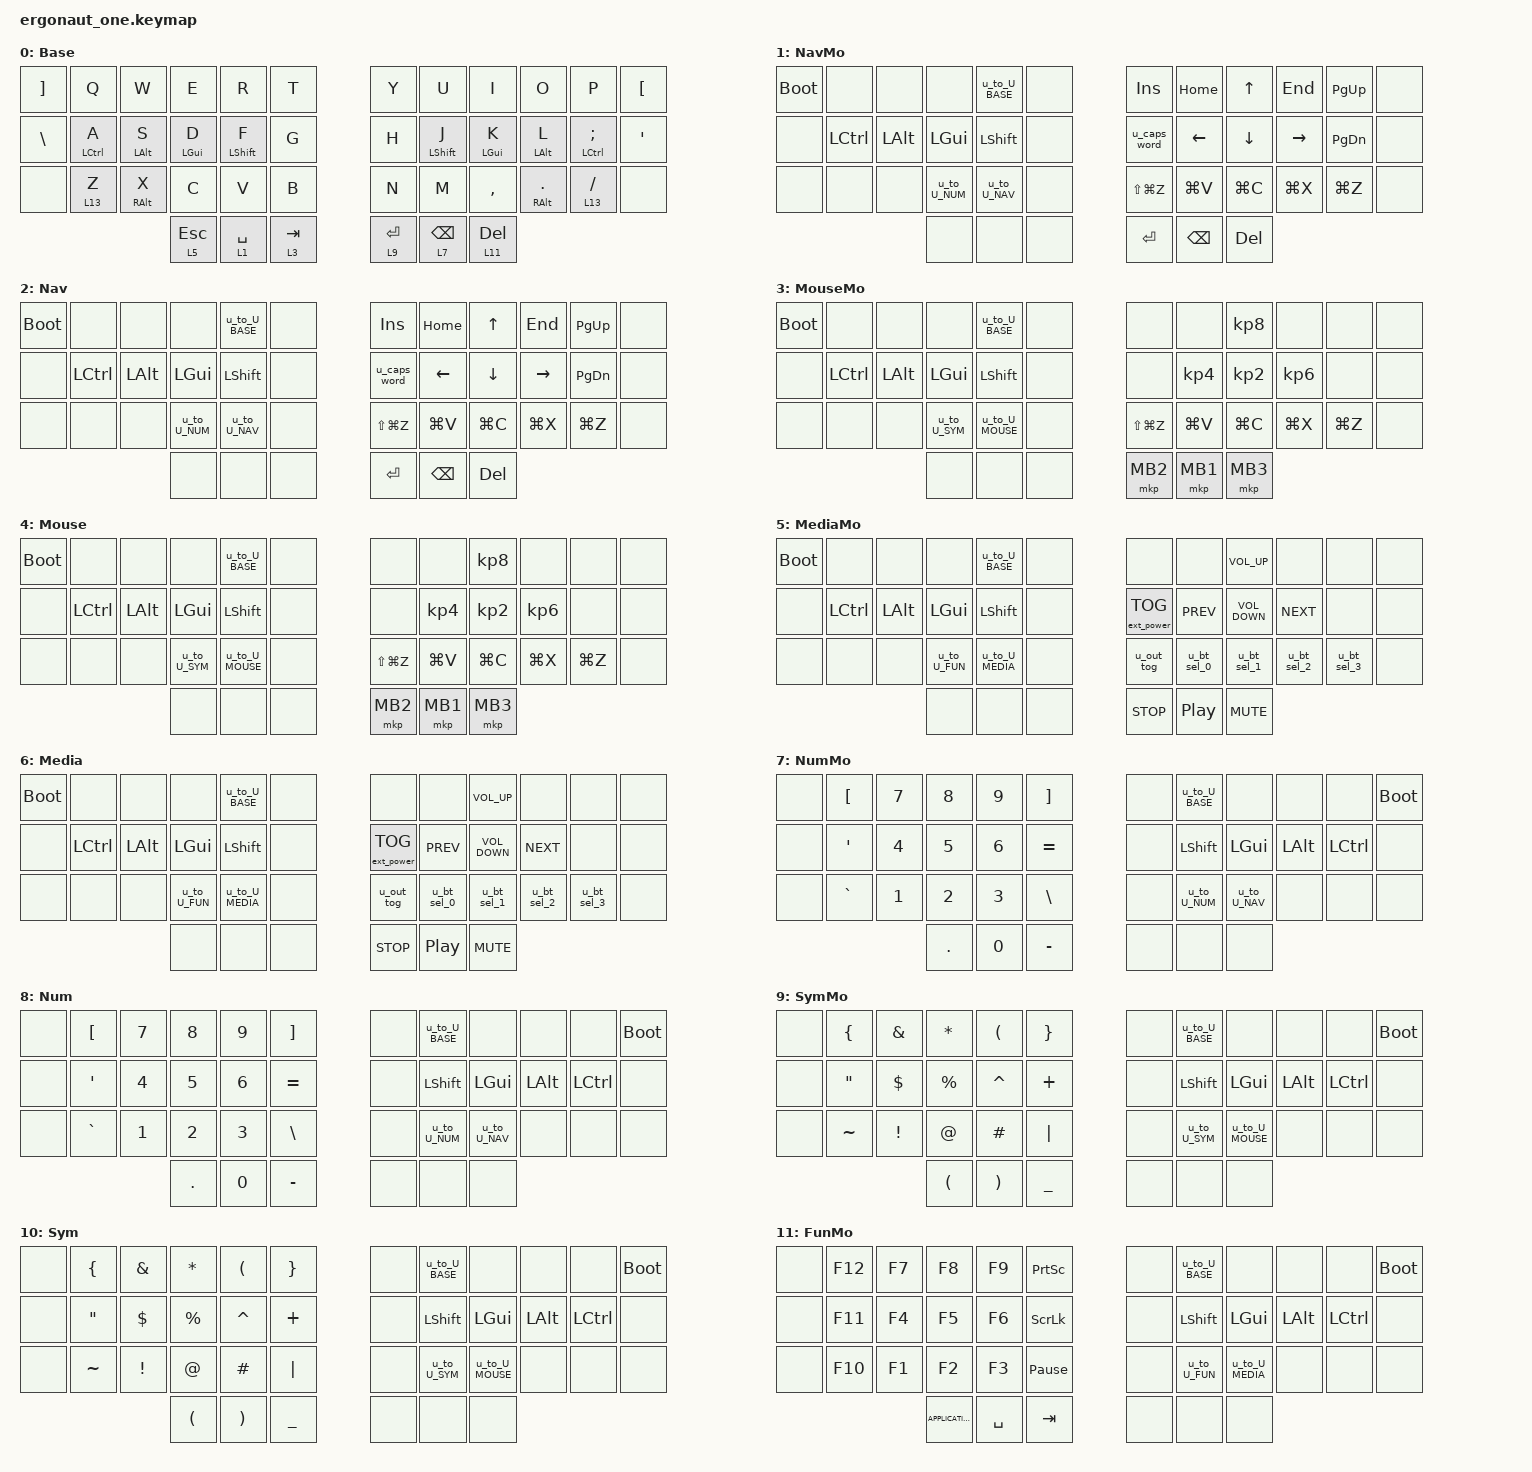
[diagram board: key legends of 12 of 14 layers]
#include <behaviors.dtsi>
#include <dt-bindings/zmk/bt.h>
#include <dt-bindings/zmk/ext_power.h>
#include <dt-bindings/zmk/keys.h>
#include <dt-bindings/zmk/mouse.h>
#include <dt-bindings/zmk/outputs.h>

#define DEF 0
#define LWR 1
#define RSE 2
#define ADJ 3

/ {
    conditional_layers { compatible = "zmk,conditional-layers"; };

    behaviors {
        hr: homerow_mods {
            compatible = "zmk,behavior-hold-tap";
            label = "HOMEROW_MODS";
            bindings = <&kp>, <&kp>;

            #binding-cells = <2>;
            tapping-term-ms = <200>;
            flavor = "tap-preferred";
        };

        u_caps_word: u_caps_word {
            compatible = "zmk,behavior-mod-morph";
            bindings = <&caps_word>, <&kp CAPSLOCK>;

            #binding-cells = <0>;
            mods = <(MOD_LSFT|MOD_RSFT)>;
        };

        u_lt: u_lt {
            compatible = "zmk,behavior-hold-tap";
            bindings = <&mo>, <&kp>;

            #binding-cells = <2>;
            tapping-term-ms = <200>;
            flavor = "tap-preferred";
        };

        u_to_U_BASE: u_to_U_BASE {
            compatible = "zmk,behavior-tap-dance";
            #binding-cells = <0>;
            tapping-term-ms = <200>;
            bindings = <&none>, <&to 0>;
        };

        u_to_U_FUN: u_to_U_FUN {
            compatible = "zmk,behavior-tap-dance";
            #binding-cells = <0>;
            tapping-term-ms = <200>;
            bindings = <&none>, <&to 12>;
        };

        u_to_U_SYM: u_to_U_SYM {
            compatible = "zmk,behavior-tap-dance";
            #binding-cells = <0>;
            bindings = <&none>, <&to 10>;

            tapping-term-ms = <200>;
        };

        u_to_U_NUM: u_to_U_NUM {
            compatible = "zmk,behavior-tap-dance";
            #binding-cells = <0>;
            tapping-term-ms = <200>;
            bindings = <&none>, <&to 8>;
        };

        u_to_U_MEDIA: u_to_U_MEDIA {
            compatible = "zmk,behavior-tap-dance";
            #binding-cells = <0>;
            tapping-term-ms = <200>;
            bindings = <&none>, <&to 6>;
        };

        u_to_U_MOUSE: u_to_U_MOUSE {
            compatible = "zmk,behavior-tap-dance";
            #binding-cells = <0>;
            tapping-term-ms = <200>;
            bindings = <&none>, <&to 4>;
        };

        u_to_U_NAV: u_to_U_NAV {
            compatible = "zmk,behavior-tap-dance";
            #binding-cells = <0>;
            tapping-term-ms = <200>;
            bindings = <&none>, <&to 2>;
        };

        u_bt_sel_0: u_bt_sel_0 {
            compatible = "zmk,behavior-mod-morph";
            bindings = <&bt BT_SEL 0>, <&u_macro_u_bt_sel_0>;

            #binding-cells = <0>;
            mods = <(MOD_LSFT|MOD_RSFT)>;
        };

        u_bt_sel_1: u_bt_sel_1 {
            compatible = "zmk,behavior-mod-morph";
            bindings = <&bt BT_SEL 1>, <&u_macro_u_bt_sel_1>;

            #binding-cells = <0>;
            mods = <(MOD_LSFT|MOD_RSFT)>;
        };

        u_bt_sel_2: u_bt_sel_2 {
            compatible = "zmk,behavior-mod-morph";
            bindings = <&bt BT_SEL 2>, <&u_macro_u_bt_sel_2>;

            #binding-cells = <0>;
            mods = <(MOD_LSFT|MOD_RSFT)>;
        };

        u_bt_sel_3: u_bt_sel_3 {
            compatible = "zmk,behavior-mod-morph";
            bindings = <&bt BT_SEL 3>, <&u_macro_u_bt_sel_3>;

            #binding-cells = <0>;
            mods = <(MOD_LSFT|MOD_RSFT)>;
        };

        u_bt_sel_4: u_bt_sel_4 {
            compatible = "zmk,behavior-mod-morph";
            bindings = <&bt BT_SEL 4>, <&u_macro_u_bt_sel_4>;

            #binding-cells = <0>;
            mods = <(MOD_LSFT|MOD_RSFT)>;
        };

        u_out_tog: u_out_tog {
            compatible = "zmk,behavior-mod-morph";
            bindings = <&out OUT_TOG>, <&out OUT_USB>;

            #binding-cells = <0>;
            mods = <(MOD_LSFT|MOD_RSFT)>;
        };
    };

    macros {
        u_macro_u_bt_sel_0: u_macro_u_bt_sel_0 {
            compatible = "zmk,behavior-macro";
            #binding-cells = <0>;
            bindings = <&bt BT_SEL 0 &bt BT_CLR>;
            label = "U_MACRO_U_BT_SEL_0";
        };

        u_macro_u_bt_sel_1: u_macro_u_bt_sel_1 {
            compatible = "zmk,behavior-macro";
            #binding-cells = <0>;
            bindings = <&bt BT_SEL 1 &bt BT_CLR>;
            label = "U_MACRO_U_BT_SEL_1";
        };

        u_macro_u_bt_sel_2: u_macro_u_bt_sel_2 {
            compatible = "zmk,behavior-macro";
            #binding-cells = <0>;
            bindings = <&bt BT_SEL 2 &bt BT_CLR>;
            label = "U_MACRO_U_BT_SEL_2";
        };

        u_macro_u_bt_sel_3: u_macro_u_bt_sel_3 {
            compatible = "zmk,behavior-macro";
            #binding-cells = <0>;
            bindings = <&bt BT_SEL 3 &bt BT_CLR>;
            label = "U_MACRO_U_BT_SEL_3";
        };

        u_macro_u_bt_sel_4: u_macro_u_bt_sel_4 {
            compatible = "zmk,behavior-macro";
            #binding-cells = <0>;
            bindings = <&bt BT_SEL 3 &bt BT_CLR>;
            label = "U_MACRO_U_BT_SEL_4";
        };
    };

    keymap {
        compatible = "zmk,keymap";

        BASE {
            bindings = <
&kp RIGHT_BRACKET  &kp Q        &kp W       &kp E        &kp R          &kp T        &kp Y           &kp U              &kp I         &kp O         &kp P           &kp LBKT
&kp BACKSLASH      &hr LCTRL A  &hr LALT S  &hr LGUI D   &hr LSHIFT F   &kp G        &kp H           &hr LSHFT J        &hr LGUI K    &hr LALT L    &hr LCTRL SEMI  &kp SQT
&none              &u_lt 13 Z   &hr RALT X  &kp C        &kp V          &kp B        &kp N           &kp M              &kp COMMA     &hr RALT DOT  &u_lt 13 FSLH   &none
                                            &u_lt 5 ESC  &u_lt 1 SPACE  &u_lt 3 TAB  &u_lt 9 RETURN  &u_lt 7 BACKSPACE  &u_lt 11 DEL
            >;

            label = "Base";
        };

        NavMo {
            label = "NavMo";
            bindings = <
&bootloader  &none      &none     &none        &u_to_U_BASE  &none  &kp INS        &kp HOME       &kp UP     &kp END    &kp PG_UP      &none
&none        &kp LCTRL  &kp LALT  &kp LGUI     &kp LSHFT     &none  &u_caps_word   &kp LEFT       &kp DOWN   &kp RIGHT  &kp PAGE_DOWN  &none
&none        &none      &none     &u_to_U_NUM  &u_to_U_NAV   &none  &kp LS(LG(Z))  &kp LG(V)      &kp LG(C)  &kp LG(X)  &kp LG(Z)      &none
                                  &none        &none         &none  &kp RET        &kp BACKSPACE  &kp DEL
            >;
        };

        NAV {
            bindings = <
&bootloader  &none      &none     &none        &u_to_U_BASE  &none  &kp INS        &kp HOME       &kp UP     &kp END    &kp PG_UP      &none
&none        &kp LCTRL  &kp LALT  &kp LGUI     &kp LSHFT     &none  &u_caps_word   &kp LEFT       &kp DOWN   &kp RIGHT  &kp PAGE_DOWN  &none
&none        &none      &none     &u_to_U_NUM  &u_to_U_NAV   &none  &kp LS(LG(Z))  &kp LG(V)      &kp LG(C)  &kp LG(X)  &kp LG(Z)      &none
                                  &none        &none         &none  &kp RET        &kp BACKSPACE  &kp DEL
            >;

            label = "Nav";
        };

        MouseMo {
            label = "MouseMo";
            bindings = <
&bootloader  &none      &none     &none        &u_to_U_BASE   &none  &none          &none      &kp KP_N8        &none      &none      &none
&none        &kp LCTRL  &kp LALT  &kp LGUI     &kp LSHIFT     &none  &none          &kp KP_N4  &kp KP_NUMBER_2  &kp KP_N6  &none      &none
&none        &none      &none     &u_to_U_SYM  &u_to_U_MOUSE  &none  &kp LS(LG(Z))  &kp LG(V)  &kp LG(C)        &kp LG(X)  &kp LG(Z)  &none
                                  &none        &none          &none  &mkp MB2       &mkp MB1   &mkp MB3
            >;
        };

        MOUSE {
            bindings = <
&bootloader  &none      &none     &none        &u_to_U_BASE   &none  &none          &none      &kp KP_N8        &none      &none      &none
&none        &kp LCTRL  &kp LALT  &kp LGUI     &kp LSHIFT     &none  &none          &kp KP_N4  &kp KP_NUMBER_2  &kp KP_N6  &none      &none
&none        &none      &none     &u_to_U_SYM  &u_to_U_MOUSE  &none  &kp LS(LG(Z))  &kp LG(V)  &kp LG(C)        &kp LG(X)  &kp LG(Z)  &none
                                  &none        &none          &none  &mkp MB2       &mkp MB1   &mkp MB3
            >;

            label = "Mouse";
        };

        MediaMo {
            label = "MediaMo";
            bindings = <
&bootloader  &none      &none     &none        &u_to_U_BASE   &none  &none              &none        &kp C_VOLUME_UP    &none        &none        &none
&none        &kp LCTRL  &kp LALT  &kp LGUI     &kp LSHIFT     &none  &ext_power EP_TOG  &kp C_PREV   &kp C_VOLUME_DOWN  &kp C_NEXT   &none        &none
&none        &none      &none     &u_to_U_FUN  &u_to_U_MEDIA  &none  &u_out_tog         &u_bt_sel_0  &u_bt_sel_1        &u_bt_sel_2  &u_bt_sel_3  &none
                                  &none        &none          &none  &kp C_STOP         &kp C_PP     &kp C_MUTE
            >;
        };

        MEDIA {
            label = "Media";
            bindings = <
&bootloader  &none      &none     &none        &u_to_U_BASE   &none  &none              &none        &kp C_VOLUME_UP    &none        &none        &none
&none        &kp LCTRL  &kp LALT  &kp LGUI     &kp LSHIFT     &none  &ext_power EP_TOG  &kp C_PREV   &kp C_VOLUME_DOWN  &kp C_NEXT   &none        &none
&none        &none      &none     &u_to_U_FUN  &u_to_U_MEDIA  &none  &u_out_tog         &u_bt_sel_0  &u_bt_sel_1        &u_bt_sel_2  &u_bt_sel_3  &none
                                  &none        &none          &none  &kp C_STOP         &kp C_PP     &kp C_MUTE
            >;
        };

        NumMo {
            label = "NumMo";
            bindings = <
&none  &kp LBKT   &kp N7  &kp N8   &kp N9  &kp RBKT   &none  &u_to_U_BASE  &none        &none     &none      &bootloader
&none  &kp SQT    &kp N4  &kp N5   &kp N6  &kp EQUAL  &none  &kp LSHIFT    &kp LGUI     &kp LALT  &kp LCTRL  &none
&none  &kp GRAVE  &kp N1  &kp N2   &kp N3  &kp BSLH   &none  &u_to_U_NUM   &u_to_U_NAV  &none     &none      &none
                          &kp DOT  &kp N0  &kp MINUS  &none  &none         &none
            >;
        };

        NUM {
            bindings = <
&none  &kp LBKT   &kp N7  &kp N8   &kp N9  &kp RBKT   &none  &u_to_U_BASE  &none        &none     &none      &bootloader
&none  &kp SQT    &kp N4  &kp N5   &kp N6  &kp EQUAL  &none  &kp LSHIFT    &kp LGUI     &kp LALT  &kp LCTRL  &none
&none  &kp GRAVE  &kp N1  &kp N2   &kp N3  &kp BSLH   &none  &u_to_U_NUM   &u_to_U_NAV  &none     &none      &none
                          &kp DOT  &kp N0  &kp MINUS  &none  &none         &none
            >;

            label = "Num";
        };

        SymMo {
            label = "SymMo";
            bindings = <
&none  &kp LEFT_BRACE     &kp AMPERSAND    &kp ASTERISK          &kp LEFT_PARENTHESIS   &kp RIGHT_BRACE  &none  &u_to_U_BASE  &none          &none     &none      &bootloader
&none  &kp DOUBLE_QUOTES  &kp DOLLAR       &kp PERCENT           &kp CARET              &kp PLUS         &none  &kp LSHIFT    &kp LGUI       &kp LALT  &kp LCTRL  &none
&none  &kp TILDE          &kp EXCLAMATION  &kp AT_SIGN           &kp HASH               &kp PIPE         &none  &u_to_U_SYM   &u_to_U_MOUSE  &none     &none      &none
                                           &kp LEFT_PARENTHESIS  &kp RIGHT_PARENTHESIS  &kp UNDERSCORE   &none  &none         &none
            >;
        };

        SYM {
            label = "Sym";
            bindings = <
&none  &kp LEFT_BRACE     &kp AMPERSAND    &kp ASTERISK          &kp LEFT_PARENTHESIS   &kp RIGHT_BRACE  &none  &u_to_U_BASE  &none          &none     &none      &bootloader
&none  &kp DOUBLE_QUOTES  &kp DOLLAR       &kp PERCENT           &kp CARET              &kp PLUS         &none  &kp LSHIFT    &kp LGUI       &kp LALT  &kp LCTRL  &none
&none  &kp TILDE          &kp EXCLAMATION  &kp AT_SIGN           &kp HASH               &kp PIPE         &none  &u_to_U_SYM   &u_to_U_MOUSE  &none     &none      &none
                                           &kp LEFT_PARENTHESIS  &kp RIGHT_PARENTHESIS  &kp UNDERSCORE   &none  &none         &none
            >;
        };

        FunMo {
            label = "FunMo";
            bindings = <
&none  &kp F12  &kp F7  &kp F8             &kp F9     &kp PSCRN        &none  &u_to_U_BASE  &none          &none     &none      &bootloader
&none  &kp F11  &kp F4  &kp F5             &kp F6     &kp SLCK         &none  &kp LSHIFT    &kp LGUI       &kp LALT  &kp LCTRL  &none
&none  &kp F10  &kp F1  &kp F2             &kp F3     &kp PAUSE_BREAK  &none  &u_to_U_FUN   &u_to_U_MEDIA  &none     &none      &none
                        &kp K_APPLICATION  &kp SPACE  &kp TAB          &none  &none         &none
            >;
        };

        FUN {
            label = "Fun";
            bindings = <
&none  &kp F12  &kp F7  &kp F8             &kp F9     &kp PSCRN        &none  &u_to_U_BASE  &none          &none     &none      &bootloader
&none  &kp F11  &kp F4  &kp F5             &kp F6     &kp SLCK         &none  &kp LSHIFT    &kp LGUI       &kp LALT  &kp LCTRL  &none
&none  &kp F10  &kp F1  &kp F2             &kp F3     &kp PAUSE_BREAK  &none  &u_to_U_FUN   &u_to_U_MEDIA  &none     &none      &none
                        &kp K_APPLICATION  &kp SPACE  &kp TAB          &none  &none         &none
            >;
        };

        BUTTON {
            bindings = <
&none  &kp LG(Z)  &kp LG(X)  &kp LG(C)  &kp LG(V)  &kp LS(LG(Z))  &kp LS(LG(Z))  &kp LG(V)  &kp LG(C)  &kp LG(X)  &kp LG(Z)  &none
&none  &kp RCTRL  &kp RALT   &kp LGUI   &kp RSHFT  &none          &none          &kp RSHFT  &kp LGUI   &kp RALT   &kp RCTRL  &none
&none  &kp LG(Z)  &kp LG(X)  &kp LG(C)  &kp LG(V)  &kp LS(LG(Z))  &kp LS(LG(Z))  &kp LG(V)  &kp LG(C)  &kp LG(X)  &kp LG(Z)  &none
                             &mkp MB3   &mkp MB1   &mkp MB2       &mkp MB2       &mkp MB1   &mkp MB3
            >;

            label = "Button";
        };
    };
};
